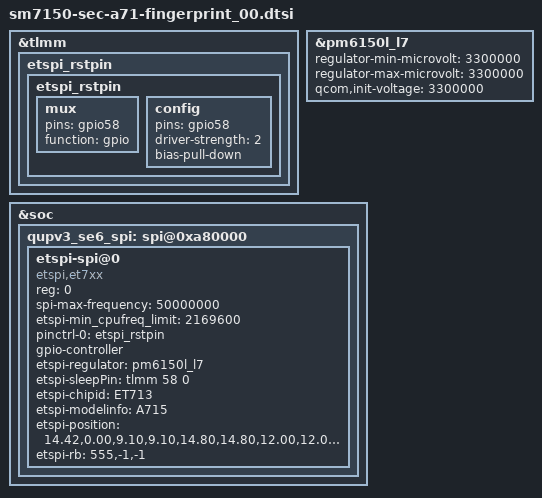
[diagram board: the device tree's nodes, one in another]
/* Copyright (c) 2013-2019, The Linux Foundation. All rights reserved.
 *
 * This program is free software; you can redistribute it and/or modify
 * it under the terms of the GNU General Public License version 2 and
 * only version 2 as published by the Free Software Foundation.
 *
 * This program is distributed in the hope that it will be useful,
 * but WITHOUT ANY WARRANTY; without even the implied warranty of
 * MERCHANTABILITY or FITNESS FOR A PARTICULAR PURPOSE.  See the
 * GNU General Public License for more details.
 */

&tlmm {
	etspi_rstpin {
		etspi_rstpin: etspi_rstpin {
			mux {
				pins = "gpio58";
				function = "gpio";
			};
			config {
				pins = "gpio58";
				driver-strength = <2>;
				bias-pull-down;
			};
		};
	};
};

&pm6150l_l7 {
	regulator-min-microvolt = <3300000>;
	regulator-max-microvolt = <3300000>;
	qcom,init-voltage = <3300000>;
};

&soc {
	qupv3_se6_spi: spi@0xa80000 {
		status = "okay";

		etspi-spi@0 {
			compatible = "etspi,et7xx";
			reg = <0>;
			spi-max-frequency = <50000000>;
			etspi-min_cpufreq_limit = <2169600>;

			pinctrl-names = "default";
			pinctrl-0 = <&etspi_rstpin>;
			
			gpio-controller;
			#gpio-cells = <2>;

			etspi-regulator = "pm6150l_l7";
			etspi-sleepPin = <&tlmm 58 0>;
			etspi-chipid = "ET713";
			etspi-modelinfo = "A715";
			etspi-position = "14.42,0.00,9.10,9.10,14.80,14.80,12.00,12.00,5.00";
			etspi-rb = "555,-1,-1";
		};
	};
};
